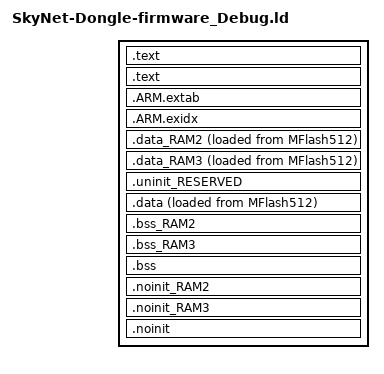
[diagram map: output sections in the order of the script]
/*
 * GENERATED FILE - DO NOT EDIT
 * (c) Code Red Technologies Ltd, 2008-2013
 * (c) NXP Semiconductors 2013-2016
 * Generated linker script file for LPC1769
 * Created from linkscript.ldt by FMCreateLinkLibraries
 * Using Freemarker v2.3.23
 * LPCXpresso v8.1.4 [Build 606] [2016-03-14]  on 05.04.2016 12:10:49
 */

INCLUDE "SkyNet-Dongle-firmware_Debug_library.ld"
INCLUDE "SkyNet-Dongle-firmware_Debug_memory.ld"

ENTRY(ResetISR)

SECTIONS
{
    /* MAIN TEXT SECTION */
    .text : ALIGN(4)
    {
        FILL(0xff)
        __vectors_start__ = ABSOLUTE(.) ;
        KEEP(*(.isr_vector))
        /* Global Section Table */
        . = ALIGN(4) ; 
        __section_table_start = .;
        __data_section_table = .;
        LONG(LOADADDR(.data));
        LONG(    ADDR(.data));
        LONG(  SIZEOF(.data));
        LONG(LOADADDR(.data_RAM2));
        LONG(    ADDR(.data_RAM2));
        LONG(  SIZEOF(.data_RAM2));
        LONG(LOADADDR(.data_RAM3));
        LONG(    ADDR(.data_RAM3));
        LONG(  SIZEOF(.data_RAM3));
        __data_section_table_end = .;
        __bss_section_table = .;
        LONG(    ADDR(.bss));
        LONG(  SIZEOF(.bss));
        LONG(    ADDR(.bss_RAM2));
        LONG(  SIZEOF(.bss_RAM2));
        LONG(    ADDR(.bss_RAM3));
        LONG(  SIZEOF(.bss_RAM3));
        __bss_section_table_end = .;
        __section_table_end = . ;
	    /* End of Global Section Table */

        *(.after_vectors*)

    } >MFlash512

    .text : ALIGN(4)    
    {
        *(.text*)
        *(.rodata .rodata.* .constdata .constdata.*)
        . = ALIGN(4);
    } > MFlash512
    /*
     * for exception handling/unwind - some Newlib functions (in common
     * with C++ and STDC++) use this. 
     */
    .ARM.extab : ALIGN(4) 
    {
        *(.ARM.extab* .gnu.linkonce.armextab.*)
    } > MFlash512
    __exidx_start = .;

    .ARM.exidx : ALIGN(4)
    {
        *(.ARM.exidx* .gnu.linkonce.armexidx.*)
    } > MFlash512
    __exidx_end = .;

    _etext = .;
        
    /* DATA section for RamBootShared */
    .data_RAM2 : ALIGN(4)
    {
        FILL(0xff)
        PROVIDE(__start_data_RAM2 = .) ;
        *(.ramfunc.$RAM2)
        *(.ramfunc.$RamBootShared)
        *(.data.$RAM2*)
        *(.data.$RamBootShared*)
        . = ALIGN(4) ;
        PROVIDE(__end_data_RAM2 = .) ;
     } > RamBootShared AT>MFlash512

    /* DATA section for RamAHB32 */
    .data_RAM3 : ALIGN(4)
    {
        FILL(0xff)
        PROVIDE(__start_data_RAM3 = .) ;
        *(.ramfunc.$RAM3)
        *(.ramfunc.$RamAHB32)
        *(.data.$RAM3*)
        *(.data.$RamAHB32*)
        . = ALIGN(4) ;
        PROVIDE(__end_data_RAM3 = .) ;
     } > RamAHB32 AT>MFlash512

    /* MAIN DATA SECTION */
    .uninit_RESERVED : ALIGN(4)
    {
        KEEP(*(.bss.$RESERVED*))
        . = ALIGN(4) ;
        _end_uninit_RESERVED = .;
    } > RamLoc32
    /* Main DATA section (RamLoc32) */
    .data : ALIGN(4)
    {
       FILL(0xff)
       _data = . ;
       *(vtable)
       *(.ramfunc*)
       *(.data*)
       . = ALIGN(4) ;
       _edata = . ;
    } > RamLoc32 AT>MFlash512
    /* BSS section for RamBootShared */
    .bss_RAM2 : ALIGN(4)
    {
       PROVIDE(__start_bss_RAM2 = .) ;
       *(.bss.$RAM2*)
       *(.bss.$RamBootShared*)
       . = ALIGN (. != 0 ? 4 : 1) ; /* avoid empty segment */
       PROVIDE(__end_bss_RAM2 = .) ;
    } > RamBootShared 
    /* BSS section for RamAHB32 */
    .bss_RAM3 : ALIGN(4)
    {
       PROVIDE(__start_bss_RAM3 = .) ;
       *(.bss.$RAM3*)
       *(.bss.$RamAHB32*)
       . = ALIGN (. != 0 ? 4 : 1) ; /* avoid empty segment */
       PROVIDE(__end_bss_RAM3 = .) ;
    } > RamAHB32 
    /* MAIN BSS SECTION */
    .bss : ALIGN(4)
    {
        _bss = .;
        *(.bss*)
        *(COMMON)
        . = ALIGN(4) ;
        _ebss = .;
        PROVIDE(end = .);
    } > RamLoc32
    /* NOINIT section for RamBootShared */
    .noinit_RAM2 (NOLOAD) : ALIGN(4)
    {
       *(.noinit.$RAM2*)
       *(.noinit.$RamBootShared*)
       . = ALIGN(4) ;
    } > RamBootShared 
    /* NOINIT section for RamAHB32 */
    .noinit_RAM3 (NOLOAD) : ALIGN(4)
    {
       *(.noinit.$RAM3*)
       *(.noinit.$RamAHB32*)
       . = ALIGN(4) ;
    } > RamAHB32 
    /* DEFAULT NOINIT SECTION */
    .noinit (NOLOAD): ALIGN(4)
    {
        _noinit = .;
        *(.noinit*) 
         . = ALIGN(4) ;
        _end_noinit = .;
    } > RamLoc32

    PROVIDE(_pvHeapStart = DEFINED(__user_heap_base) ? __user_heap_base : .);
    PROVIDE(_vStackTop = DEFINED(__user_stack_top) ? __user_stack_top : __top_RamLoc32 - 0);

    /* ## Create checksum value (used in startup) ## */
    PROVIDE(__valid_user_code_checksum = 0 - 
                                         (_vStackTop 
                                         + (ResetISR + 1) 
                                         + (NMI_Handler + 1) 
                                         + (HardFault_Handler + 1) 
                                         + (( DEFINED(MemManage_Handler) ? MemManage_Handler : 0 ) + 1)   /* MemManage_Handler may not be defined */
                                         + (( DEFINED(BusFault_Handler) ? BusFault_Handler : 0 ) + 1)     /* BusFault_Handler may not be defined */
                                         + (( DEFINED(UsageFault_Handler) ? UsageFault_Handler : 0 ) + 1) /* UsageFault_Handler may not be defined */
                                         ) );
}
